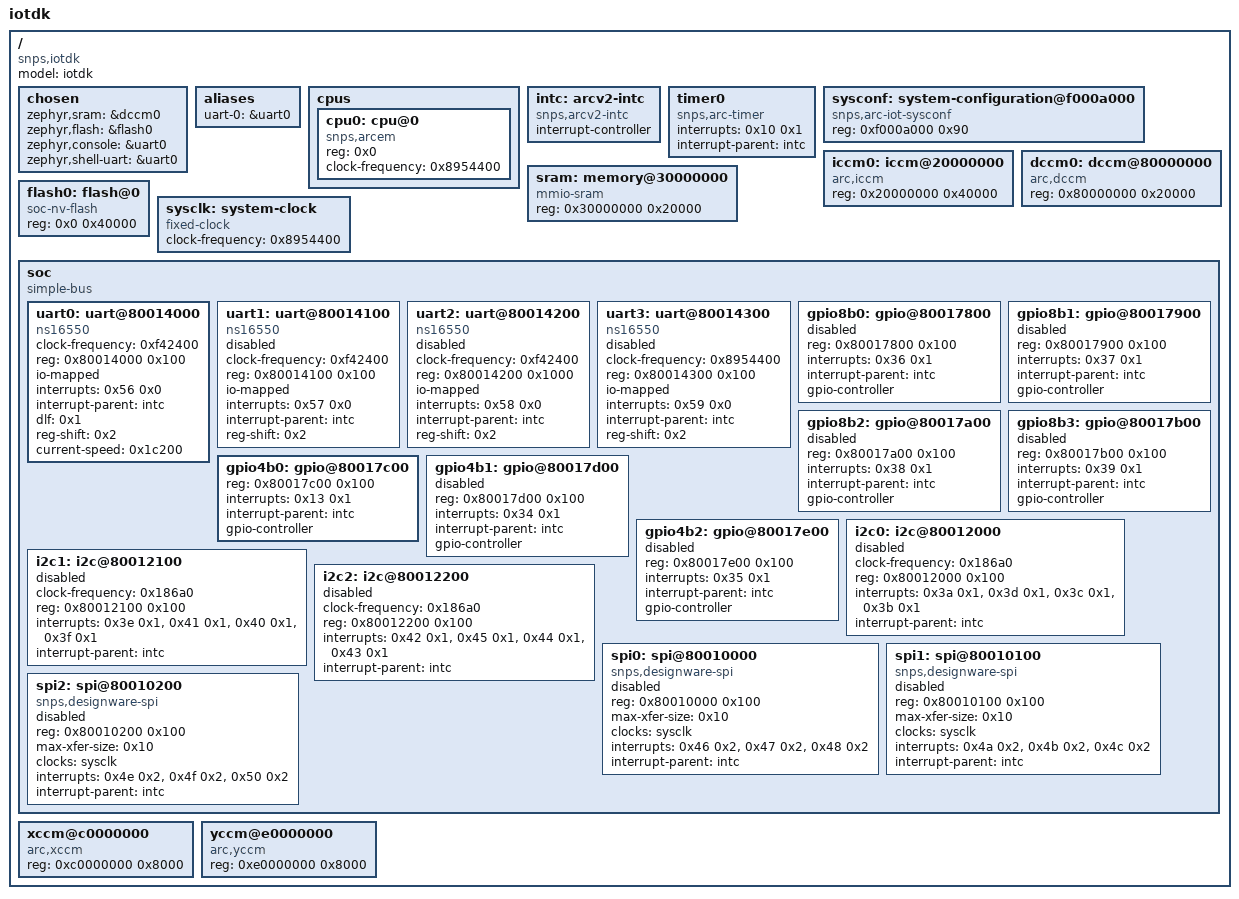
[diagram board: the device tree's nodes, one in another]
/dts-v1/;

/* node '/' defined in zephyr/dts/common/skeleton.dtsi:9 */
/ {
	#address-cells = < 0x1 >;  /* in zephyr/dts/common/skeleton.dtsi:10 */
	#size-cells = < 0x1 >;     /* in zephyr/dts/common/skeleton.dtsi:11 */
	model = "iotdk";           /* in zephyr/boards/snps/iotdk/iotdk.dts:13 */
	compatible = "snps,iotdk",
	             "snps,iotdk"; /* in zephyr/boards/snps/iotdk/iotdk.dts:14 */

	/* node '/chosen' defined in zephyr/dts/common/skeleton.dtsi:13 */
	chosen {
		zephyr,sram = &dccm0;       /* in zephyr/boards/snps/iotdk/iotdk.dts:21 */
		zephyr,flash = &flash0;     /* in zephyr/boards/snps/iotdk/iotdk.dts:22 */
		zephyr,console = &uart0;    /* in zephyr/boards/snps/iotdk/iotdk.dts:23 */
		zephyr,shell-uart = &uart0; /* in zephyr/boards/snps/iotdk/iotdk.dts:24 */
	};

	/* node '/aliases' defined in zephyr/dts/common/skeleton.dtsi:15 */
	aliases {
		uart-0 = &uart0; /* in zephyr/boards/snps/iotdk/iotdk.dts:17 */
	};

	/* node '/cpus' defined in zephyr/dts/arc/synopsys/arc_iot.dtsi:13 */
	cpus {
		#address-cells = < 0x1 >; /* in zephyr/dts/arc/synopsys/arc_iot.dtsi:14 */
		#size-cells = < 0x0 >;    /* in zephyr/dts/arc/synopsys/arc_iot.dtsi:15 */

		/* node '/cpus/cpu@0' defined in zephyr/dts/arc/synopsys/arc_iot.dtsi:17 */
		cpu0: cpu@0 {
			device_type = "cpu";             /* in zephyr/dts/arc/synopsys/arc_iot.dtsi:18 */
			compatible = "snps,arcem";       /* in zephyr/dts/arc/synopsys/arc_iot.dtsi:19 */
			reg = < 0x0 >;                   /* in zephyr/dts/arc/synopsys/arc_iot.dtsi:20 */
			clock-frequency = < 0x8954400 >; /* in zephyr/boards/snps/iotdk/iotdk.dts:39 */
		};
	};

	/* node '/arcv2-intc' defined in zephyr/dts/arc/synopsys/arc_iot.dtsi:24 */
	intc: arcv2-intc {
		compatible = "snps,arcv2-intc"; /* in zephyr/dts/arc/synopsys/arc_iot.dtsi:25 */
		interrupt-controller;           /* in zephyr/dts/arc/synopsys/arc_iot.dtsi:26 */
		#interrupt-cells = < 0x2 >;     /* in zephyr/dts/arc/synopsys/arc_iot.dtsi:27 */
		phandle = < 0x1 >;              /* in zephyr/dts/arc/synopsys/arc_iot.dtsi:33 */
	};

	/* node '/timer0' defined in zephyr/dts/arc/synopsys/arc_iot.dtsi:30 */
	timer0: timer0 {
		compatible = "snps,arc-timer"; /* in zephyr/dts/arc/synopsys/arc_iot.dtsi:31 */
		interrupts = < 0x10 0x1 >;     /* in zephyr/dts/arc/synopsys/arc_iot.dtsi:32 */
		interrupt-parent = < &intc >;  /* in zephyr/dts/arc/synopsys/arc_iot.dtsi:33 */
	};

	/* node '/system-configuration@f000a000' defined in zephyr/dts/arc/synopsys/arc_iot.dtsi:36 */
	sysconf: system-configuration@f000a000 {
		compatible = "snps,arc-iot-sysconf"; /* in zephyr/dts/arc/synopsys/arc_iot.dtsi:37 */
		reg = < 0xf000a000 0x90 >;           /* in zephyr/dts/arc/synopsys/arc_iot.dtsi:38 */
	};

	/* node '/iccm@20000000' defined in zephyr/dts/arc/synopsys/arc_iot.dtsi:41 */
	iccm0: iccm@20000000 {
		compatible = "arc,iccm";      /* in zephyr/dts/arc/synopsys/arc_iot.dtsi:42 */
		reg = < 0x20000000 0x40000 >; /* in zephyr/dts/arc/synopsys/arc_iot.dtsi:43 */
	};

	/* node '/dccm@80000000' defined in zephyr/dts/arc/synopsys/arc_iot.dtsi:46 */
	dccm0: dccm@80000000 {
		compatible = "arc,dccm";      /* in zephyr/dts/arc/synopsys/arc_iot.dtsi:47 */
		reg = < 0x80000000 0x20000 >; /* in zephyr/dts/arc/synopsys/arc_iot.dtsi:48 */
	};

	/* node '/memory@30000000' defined in zephyr/dts/arc/synopsys/arc_iot.dtsi:51 */
	sram: memory@30000000 {
		compatible = "mmio-sram";     /* in zephyr/dts/arc/synopsys/arc_iot.dtsi:52 */
		reg = < 0x30000000 0x20000 >; /* in zephyr/dts/arc/synopsys/arc_iot.dtsi:53 */
	};

	/* node '/flash@0' defined in zephyr/dts/arc/synopsys/arc_iot.dtsi:56 */
	flash0: flash@0 {
		compatible = "soc-nv-flash"; /* in zephyr/dts/arc/synopsys/arc_iot.dtsi:57 */
		reg = < 0x0 0x40000 >;       /* in zephyr/dts/arc/synopsys/arc_iot.dtsi:58 */
	};

	/* node '/system-clock' defined in zephyr/dts/arc/synopsys/arc_iot.dtsi:61 */
	sysclk: system-clock {
		compatible = "fixed-clock";      /* in zephyr/dts/arc/synopsys/arc_iot.dtsi:62 */
		clock-frequency = < 0x8954400 >; /* in zephyr/dts/arc/synopsys/arc_iot.dtsi:63 */
		#clock-cells = < 0x0 >;          /* in zephyr/dts/arc/synopsys/arc_iot.dtsi:64 */
		phandle = < 0x2 >;               /* in zephyr/dts/arc/synopsys/arc_iot.dtsi:234 */
	};

	/* node '/soc' defined in zephyr/dts/arc/synopsys/arc_iot.dtsi:67 */
	soc {
		#address-cells = < 0x1 >;  /* in zephyr/dts/arc/synopsys/arc_iot.dtsi:68 */
		#size-cells = < 0x1 >;     /* in zephyr/dts/arc/synopsys/arc_iot.dtsi:69 */
		compatible = "simple-bus"; /* in zephyr/dts/arc/synopsys/arc_iot.dtsi:70 */
		ranges;                    /* in zephyr/dts/arc/synopsys/arc_iot.dtsi:71 */

		/* node '/soc/uart@80014000' defined in zephyr/dts/arc/synopsys/arc_iot.dtsi:73 */
		uart0: uart@80014000 {
			compatible = "ns16550";         /* in zephyr/dts/arc/synopsys/arc_iot.dtsi:74 */
			clock-frequency = < 0xf42400 >; /* in zephyr/dts/arc/synopsys/arc_iot.dtsi:75 */
			reg = < 0x80014000 0x100 >;     /* in zephyr/dts/arc/synopsys/arc_iot.dtsi:76 */
			io-mapped;                      /* in zephyr/dts/arc/synopsys/arc_iot.dtsi:77 */
			interrupts = < 0x56 0x0 >;      /* in zephyr/dts/arc/synopsys/arc_iot.dtsi:78 */
			interrupt-parent = < &intc >;   /* in zephyr/dts/arc/synopsys/arc_iot.dtsi:79 */
			dlf = < 0x1 >;                  /* in zephyr/dts/arc/synopsys/arc_iot.dtsi:80 */
			reg-shift = < 0x2 >;            /* in zephyr/dts/arc/synopsys/arc_iot.dtsi:81 */
			status = "okay";                /* in zephyr/boards/snps/iotdk/iotdk.dts:43 */
			current-speed = < 0x1c200 >;    /* in zephyr/boards/snps/iotdk/iotdk.dts:44 */
		};

		/* node '/soc/uart@80014100' defined in zephyr/dts/arc/synopsys/arc_iot.dtsi:84 */
		uart1: uart@80014100 {
			compatible = "ns16550";         /* in zephyr/dts/arc/synopsys/arc_iot.dtsi:85 */
			clock-frequency = < 0xf42400 >; /* in zephyr/dts/arc/synopsys/arc_iot.dtsi:86 */
			reg = < 0x80014100 0x100 >;     /* in zephyr/dts/arc/synopsys/arc_iot.dtsi:87 */
			io-mapped;                      /* in zephyr/dts/arc/synopsys/arc_iot.dtsi:88 */
			interrupts = < 0x57 0x0 >;      /* in zephyr/dts/arc/synopsys/arc_iot.dtsi:89 */
			interrupt-parent = < &intc >;   /* in zephyr/dts/arc/synopsys/arc_iot.dtsi:90 */
			reg-shift = < 0x2 >;            /* in zephyr/dts/arc/synopsys/arc_iot.dtsi:91 */
			status = "disabled";            /* in zephyr/dts/arc/synopsys/arc_iot.dtsi:92 */
		};

		/* node '/soc/uart@80014200' defined in zephyr/dts/arc/synopsys/arc_iot.dtsi:95 */
		uart2: uart@80014200 {
			compatible = "ns16550";         /* in zephyr/dts/arc/synopsys/arc_iot.dtsi:96 */
			clock-frequency = < 0xf42400 >; /* in zephyr/dts/arc/synopsys/arc_iot.dtsi:97 */
			reg = < 0x80014200 0x1000 >;    /* in zephyr/dts/arc/synopsys/arc_iot.dtsi:98 */
			io-mapped;                      /* in zephyr/dts/arc/synopsys/arc_iot.dtsi:99 */
			interrupts = < 0x58 0x0 >;      /* in zephyr/dts/arc/synopsys/arc_iot.dtsi:100 */
			interrupt-parent = < &intc >;   /* in zephyr/dts/arc/synopsys/arc_iot.dtsi:101 */
			reg-shift = < 0x2 >;            /* in zephyr/dts/arc/synopsys/arc_iot.dtsi:102 */
			status = "disabled";            /* in zephyr/dts/arc/synopsys/arc_iot.dtsi:103 */
		};

		/* node '/soc/uart@80014300' defined in zephyr/dts/arc/synopsys/arc_iot.dtsi:106 */
		uart3: uart@80014300 {
			compatible = "ns16550";          /* in zephyr/dts/arc/synopsys/arc_iot.dtsi:107 */
			clock-frequency = < 0x8954400 >; /* in zephyr/dts/arc/synopsys/arc_iot.dtsi:108 */
			reg = < 0x80014300 0x100 >;      /* in zephyr/dts/arc/synopsys/arc_iot.dtsi:109 */
			io-mapped;                       /* in zephyr/dts/arc/synopsys/arc_iot.dtsi:110 */
			interrupts = < 0x59 0x0 >;       /* in zephyr/dts/arc/synopsys/arc_iot.dtsi:111 */
			interrupt-parent = < &intc >;    /* in zephyr/dts/arc/synopsys/arc_iot.dtsi:112 */
			reg-shift = < 0x2 >;             /* in zephyr/dts/arc/synopsys/arc_iot.dtsi:113 */
			status = "disabled";             /* in zephyr/dts/arc/synopsys/arc_iot.dtsi:114 */
		};

		/* node '/soc/gpio@80017800' defined in zephyr/dts/arc/synopsys/arc_iot.dtsi:117 */
		gpio8b0: gpio@80017800 {
			reg = < 0x80017800 0x100 >;   /* in zephyr/dts/arc/synopsys/arc_iot.dtsi:118 */
			interrupts = < 0x36 0x1 >;    /* in zephyr/dts/arc/synopsys/arc_iot.dtsi:119 */
			interrupt-parent = < &intc >; /* in zephyr/dts/arc/synopsys/arc_iot.dtsi:120 */
			gpio-controller;              /* in zephyr/dts/arc/synopsys/arc_iot.dtsi:122 */
			#gpio-cells = < 0x2 >;        /* in zephyr/dts/arc/synopsys/arc_iot.dtsi:123 */
			status = "disabled";          /* in zephyr/dts/arc/synopsys/arc_iot.dtsi:125 */
		};

		/* node '/soc/gpio@80017900' defined in zephyr/dts/arc/synopsys/arc_iot.dtsi:128 */
		gpio8b1: gpio@80017900 {
			reg = < 0x80017900 0x100 >;   /* in zephyr/dts/arc/synopsys/arc_iot.dtsi:129 */
			interrupts = < 0x37 0x1 >;    /* in zephyr/dts/arc/synopsys/arc_iot.dtsi:130 */
			interrupt-parent = < &intc >; /* in zephyr/dts/arc/synopsys/arc_iot.dtsi:131 */
			gpio-controller;              /* in zephyr/dts/arc/synopsys/arc_iot.dtsi:133 */
			#gpio-cells = < 0x2 >;        /* in zephyr/dts/arc/synopsys/arc_iot.dtsi:134 */
			status = "disabled";          /* in zephyr/dts/arc/synopsys/arc_iot.dtsi:136 */
		};

		/* node '/soc/gpio@80017a00' defined in zephyr/dts/arc/synopsys/arc_iot.dtsi:139 */
		gpio8b2: gpio@80017a00 {
			reg = < 0x80017a00 0x100 >;   /* in zephyr/dts/arc/synopsys/arc_iot.dtsi:140 */
			interrupts = < 0x38 0x1 >;    /* in zephyr/dts/arc/synopsys/arc_iot.dtsi:141 */
			interrupt-parent = < &intc >; /* in zephyr/dts/arc/synopsys/arc_iot.dtsi:142 */
			gpio-controller;              /* in zephyr/dts/arc/synopsys/arc_iot.dtsi:144 */
			#gpio-cells = < 0x2 >;        /* in zephyr/dts/arc/synopsys/arc_iot.dtsi:145 */
			status = "disabled";          /* in zephyr/dts/arc/synopsys/arc_iot.dtsi:147 */
		};

		/* node '/soc/gpio@80017b00' defined in zephyr/dts/arc/synopsys/arc_iot.dtsi:150 */
		gpio8b3: gpio@80017b00 {
			reg = < 0x80017b00 0x100 >;   /* in zephyr/dts/arc/synopsys/arc_iot.dtsi:151 */
			interrupts = < 0x39 0x1 >;    /* in zephyr/dts/arc/synopsys/arc_iot.dtsi:152 */
			interrupt-parent = < &intc >; /* in zephyr/dts/arc/synopsys/arc_iot.dtsi:153 */
			gpio-controller;              /* in zephyr/dts/arc/synopsys/arc_iot.dtsi:155 */
			#gpio-cells = < 0x2 >;        /* in zephyr/dts/arc/synopsys/arc_iot.dtsi:156 */
			status = "disabled";          /* in zephyr/dts/arc/synopsys/arc_iot.dtsi:158 */
		};

		/* node '/soc/gpio@80017c00' defined in zephyr/dts/arc/synopsys/arc_iot.dtsi:161 */
		gpio4b0: gpio@80017c00 {
			reg = < 0x80017c00 0x100 >;   /* in zephyr/dts/arc/synopsys/arc_iot.dtsi:162 */
			interrupts = < 0x13 0x1 >;    /* in zephyr/dts/arc/synopsys/arc_iot.dtsi:163 */
			interrupt-parent = < &intc >; /* in zephyr/dts/arc/synopsys/arc_iot.dtsi:164 */
			gpio-controller;              /* in zephyr/dts/arc/synopsys/arc_iot.dtsi:166 */
			#gpio-cells = < 0x2 >;        /* in zephyr/dts/arc/synopsys/arc_iot.dtsi:167 */
		};

		/* node '/soc/gpio@80017d00' defined in zephyr/dts/arc/synopsys/arc_iot.dtsi:170 */
		gpio4b1: gpio@80017d00 {
			reg = < 0x80017d00 0x100 >;   /* in zephyr/dts/arc/synopsys/arc_iot.dtsi:171 */
			interrupts = < 0x34 0x1 >;    /* in zephyr/dts/arc/synopsys/arc_iot.dtsi:172 */
			interrupt-parent = < &intc >; /* in zephyr/dts/arc/synopsys/arc_iot.dtsi:173 */
			gpio-controller;              /* in zephyr/dts/arc/synopsys/arc_iot.dtsi:175 */
			#gpio-cells = < 0x2 >;        /* in zephyr/dts/arc/synopsys/arc_iot.dtsi:176 */
			status = "disabled";          /* in zephyr/dts/arc/synopsys/arc_iot.dtsi:178 */
		};

		/* node '/soc/gpio@80017e00' defined in zephyr/dts/arc/synopsys/arc_iot.dtsi:181 */
		gpio4b2: gpio@80017e00 {
			reg = < 0x80017e00 0x100 >;   /* in zephyr/dts/arc/synopsys/arc_iot.dtsi:182 */
			interrupts = < 0x35 0x1 >;    /* in zephyr/dts/arc/synopsys/arc_iot.dtsi:183 */
			interrupt-parent = < &intc >; /* in zephyr/dts/arc/synopsys/arc_iot.dtsi:184 */
			gpio-controller;              /* in zephyr/dts/arc/synopsys/arc_iot.dtsi:186 */
			#gpio-cells = < 0x2 >;        /* in zephyr/dts/arc/synopsys/arc_iot.dtsi:187 */
			status = "disabled";          /* in zephyr/dts/arc/synopsys/arc_iot.dtsi:189 */
		};

		/* node '/soc/i2c@80012000' defined in zephyr/dts/arc/synopsys/arc_iot.dtsi:192 */
		i2c0: i2c@80012000 {
			clock-frequency = < 0x186a0 >; /* in zephyr/dts/arc/synopsys/arc_iot.dtsi:193 */
			#address-cells = < 0x1 >;      /* in zephyr/dts/arc/synopsys/arc_iot.dtsi:194 */
			#size-cells = < 0x0 >;         /* in zephyr/dts/arc/synopsys/arc_iot.dtsi:195 */
			reg = < 0x80012000 0x100 >;    /* in zephyr/dts/arc/synopsys/arc_iot.dtsi:196 */
			interrupts = < 0x3a 0x1 >,
			             < 0x3d 0x1 >,
			             < 0x3c 0x1 >,
			             < 0x3b 0x1 >;     /* in zephyr/dts/arc/synopsys/arc_iot.dtsi:197 */
			interrupt-names = "error",
			                  "stop",
			                  "tx",
			                  "rx";        /* in zephyr/dts/arc/synopsys/arc_iot.dtsi:198 */
			interrupt-parent = < &intc >;  /* in zephyr/dts/arc/synopsys/arc_iot.dtsi:199 */
			status = "disabled";           /* in zephyr/dts/arc/synopsys/arc_iot.dtsi:201 */
		};

		/* node '/soc/i2c@80012100' defined in zephyr/dts/arc/synopsys/arc_iot.dtsi:204 */
		i2c1: i2c@80012100 {
			clock-frequency = < 0x186a0 >; /* in zephyr/dts/arc/synopsys/arc_iot.dtsi:205 */
			#address-cells = < 0x1 >;      /* in zephyr/dts/arc/synopsys/arc_iot.dtsi:206 */
			#size-cells = < 0x0 >;         /* in zephyr/dts/arc/synopsys/arc_iot.dtsi:207 */
			reg = < 0x80012100 0x100 >;    /* in zephyr/dts/arc/synopsys/arc_iot.dtsi:208 */
			interrupts = < 0x3e 0x1 >,
			             < 0x41 0x1 >,
			             < 0x40 0x1 >,
			             < 0x3f 0x1 >;     /* in zephyr/dts/arc/synopsys/arc_iot.dtsi:209 */
			interrupt-names = "error",
			                  "stop",
			                  "tx",
			                  "rx";        /* in zephyr/dts/arc/synopsys/arc_iot.dtsi:210 */
			interrupt-parent = < &intc >;  /* in zephyr/dts/arc/synopsys/arc_iot.dtsi:211 */
			status = "disabled";           /* in zephyr/dts/arc/synopsys/arc_iot.dtsi:213 */
		};

		/* node '/soc/i2c@80012200' defined in zephyr/dts/arc/synopsys/arc_iot.dtsi:216 */
		i2c2: i2c@80012200 {
			clock-frequency = < 0x186a0 >; /* in zephyr/dts/arc/synopsys/arc_iot.dtsi:217 */
			#address-cells = < 0x1 >;      /* in zephyr/dts/arc/synopsys/arc_iot.dtsi:218 */
			#size-cells = < 0x0 >;         /* in zephyr/dts/arc/synopsys/arc_iot.dtsi:219 */
			reg = < 0x80012200 0x100 >;    /* in zephyr/dts/arc/synopsys/arc_iot.dtsi:220 */
			interrupts = < 0x42 0x1 >,
			             < 0x45 0x1 >,
			             < 0x44 0x1 >,
			             < 0x43 0x1 >;     /* in zephyr/dts/arc/synopsys/arc_iot.dtsi:221 */
			interrupt-names = "error",
			                  "stop",
			                  "tx",
			                  "rx";        /* in zephyr/dts/arc/synopsys/arc_iot.dtsi:222 */
			interrupt-parent = < &intc >;  /* in zephyr/dts/arc/synopsys/arc_iot.dtsi:223 */
			status = "disabled";           /* in zephyr/dts/arc/synopsys/arc_iot.dtsi:225 */
		};

		/* node '/soc/spi@80010000' defined in zephyr/dts/arc/synopsys/arc_iot.dtsi:228 */
		spi0: spi@80010000 {
			compatible = "snps,designware-spi"; /* in zephyr/dts/arc/synopsys/arc_iot.dtsi:229 */
			#address-cells = < 0x1 >;           /* in zephyr/dts/arc/synopsys/arc_iot.dtsi:230 */
			#size-cells = < 0x0 >;              /* in zephyr/dts/arc/synopsys/arc_iot.dtsi:231 */
			reg = < 0x80010000 0x100 >;         /* in zephyr/dts/arc/synopsys/arc_iot.dtsi:232 */
			max-xfer-size = < 0x10 >;           /* in zephyr/dts/arc/synopsys/arc_iot.dtsi:233 */
			clocks = < &sysclk >;               /* in zephyr/dts/arc/synopsys/arc_iot.dtsi:234 */
			interrupts = < 0x46 0x2 >,
			             < 0x47 0x2 >,
			             < 0x48 0x2 >;          /* in zephyr/dts/arc/synopsys/arc_iot.dtsi:235 */
			interrupt-names = "err-int",
			                  "rx-avail",
			                  "tx-req";         /* in zephyr/dts/arc/synopsys/arc_iot.dtsi:236 */
			interrupt-parent = < &intc >;       /* in zephyr/dts/arc/synopsys/arc_iot.dtsi:237 */
			status = "disabled";                /* in zephyr/dts/arc/synopsys/arc_iot.dtsi:238 */
		};

		/* node '/soc/spi@80010100' defined in zephyr/dts/arc/synopsys/arc_iot.dtsi:241 */
		spi1: spi@80010100 {
			compatible = "snps,designware-spi"; /* in zephyr/dts/arc/synopsys/arc_iot.dtsi:242 */
			#address-cells = < 0x1 >;           /* in zephyr/dts/arc/synopsys/arc_iot.dtsi:243 */
			#size-cells = < 0x0 >;              /* in zephyr/dts/arc/synopsys/arc_iot.dtsi:244 */
			reg = < 0x80010100 0x100 >;         /* in zephyr/dts/arc/synopsys/arc_iot.dtsi:245 */
			max-xfer-size = < 0x10 >;           /* in zephyr/dts/arc/synopsys/arc_iot.dtsi:246 */
			clocks = < &sysclk >;               /* in zephyr/dts/arc/synopsys/arc_iot.dtsi:247 */
			interrupts = < 0x4a 0x2 >,
			             < 0x4b 0x2 >,
			             < 0x4c 0x2 >;          /* in zephyr/dts/arc/synopsys/arc_iot.dtsi:248 */
			interrupt-names = "err-int",
			                  "rx-avail",
			                  "tx-req";         /* in zephyr/dts/arc/synopsys/arc_iot.dtsi:249 */
			interrupt-parent = < &intc >;       /* in zephyr/dts/arc/synopsys/arc_iot.dtsi:250 */
			status = "disabled";                /* in zephyr/dts/arc/synopsys/arc_iot.dtsi:251 */
		};

		/* node '/soc/spi@80010200' defined in zephyr/dts/arc/synopsys/arc_iot.dtsi:254 */
		spi2: spi@80010200 {
			compatible = "snps,designware-spi"; /* in zephyr/dts/arc/synopsys/arc_iot.dtsi:255 */
			#address-cells = < 0x1 >;           /* in zephyr/dts/arc/synopsys/arc_iot.dtsi:256 */
			#size-cells = < 0x0 >;              /* in zephyr/dts/arc/synopsys/arc_iot.dtsi:257 */
			reg = < 0x80010200 0x100 >;         /* in zephyr/dts/arc/synopsys/arc_iot.dtsi:258 */
			max-xfer-size = < 0x10 >;           /* in zephyr/dts/arc/synopsys/arc_iot.dtsi:259 */
			clocks = < &sysclk >;               /* in zephyr/dts/arc/synopsys/arc_iot.dtsi:260 */
			interrupts = < 0x4e 0x2 >,
			             < 0x4f 0x2 >,
			             < 0x50 0x2 >;          /* in zephyr/dts/arc/synopsys/arc_iot.dtsi:261 */
			interrupt-names = "err-int",
			                  "rx-avail",
			                  "tx-req";         /* in zephyr/dts/arc/synopsys/arc_iot.dtsi:262 */
			interrupt-parent = < &intc >;       /* in zephyr/dts/arc/synopsys/arc_iot.dtsi:263 */
			status = "disabled";                /* in zephyr/dts/arc/synopsys/arc_iot.dtsi:264 */
		};
	};

	/* node '/xccm@c0000000' defined in zephyr/boards/snps/iotdk/iotdk.dts:27 */
	xccm@c0000000 {
		compatible = "arc,xccm";     /* in zephyr/boards/snps/iotdk/iotdk.dts:28 */
		reg = < 0xc0000000 0x8000 >; /* in zephyr/boards/snps/iotdk/iotdk.dts:29 */
	};

	/* node '/yccm@e0000000' defined in zephyr/boards/snps/iotdk/iotdk.dts:32 */
	yccm@e0000000 {
		compatible = "arc,yccm";     /* in zephyr/boards/snps/iotdk/iotdk.dts:33 */
		reg = < 0xe0000000 0x8000 >; /* in zephyr/boards/snps/iotdk/iotdk.dts:34 */
	};
};
